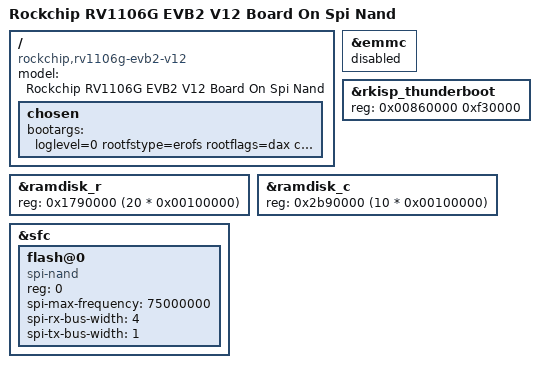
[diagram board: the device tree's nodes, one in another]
// SPDX-License-Identifier: (GPL-2.0+ OR MIT)
/*
 * Copyright (c) 2024 Rockchip Electronics Co., Ltd.
 */

/dts-v1/;

#include "rv1106g-evb2-v10.dts"

/ {
	model = "Rockchip RV1106G EVB2 V12 Board On Spi Nand";
	compatible = "rockchip,rv1106g-evb2-v12", "rockchip,rv1106";

	chosen {
		bootargs = "loglevel=0 rootfstype=erofs rootflags=dax console=ttyFIQ0 root=/dev/rd0 snd_soc_core.prealloc_buffer_size_kbytes=16 coherent_pool=0 driver_async_probe=dwmmc_rockchip";
	};
};

/delete-node/ &thunder_boot_spi_nor;

&emmc {
	status = "disabled";
};

&rkisp_thunderboot {
	/* reg's offset MUST match with RTOS */
	/*
	 * vicap, capture raw10, ceil(w*10/8/256)*256*h *4(buf num)
	 * e.g. 2304x1296: 0xf30000
	 */
	reg = <0x00860000 0xf30000>;
};

&ramdisk_r {
	reg = <0x1790000 (20 * 0x00100000)>;
};

&ramdisk_c {
	reg = <0x2b90000 (10 * 0x00100000)>;
};

&sfc {
	status = "okay";

	flash@0 {
		compatible = "spi-nand";
		reg = <0>;
		spi-max-frequency = <75000000>;
		spi-rx-bus-width = <4>;
		spi-tx-bus-width = <1>;
	};
};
